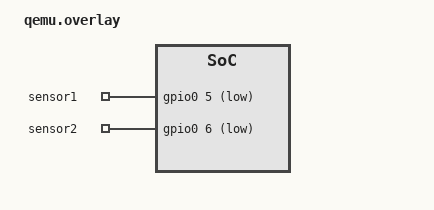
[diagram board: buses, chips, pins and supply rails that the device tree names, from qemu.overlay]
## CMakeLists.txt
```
# SPDX-License-Identifier: Apache-2.0

cmake_minimum_required(VERSION 3.20.0)

find_package(Zephyr REQUIRED HINTS $ENV{ZEPHYR_BASE})
project(my_app)

set(ZEPHYR_EXTRA_KCONFIG_FILES ${CMAKE_CURRENT_SOURCE_DIR}/Kconfig)
set(ZEPHYR_EXTRA_MODULES "${CMAKE_CURRENT_SOURCE_DIR}/camera_service/")


zephyr_include_directories(
    ${CMAKE_CURRENT_SOURCE_DIR}/include
    ${CMAKE_CURRENT_SOURCE_DIR}/camera_service/include
)
target_sources(app PRIVATE 
    src/main.c 
    src/sensor.c 
    src/ntp.c
    src/http_client.c
    src/http_sender.c
    src/camera_capture.c
    camera_service/src/camera_service.c)
```

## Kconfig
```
mainmenu "Radar Simplificado Configuration"

source "Kconfig.zephyr"

menu "My Project Options"

config RADAR_SENSOR_DISTANCE_MM
    int "Distância entre os sensores dada em milímetros."
    default 2000

config RADAR_SPEED_LIMIT_KMH
    int "Limite da via em Km por hora."
    default 60

config RADAR_CAMERA_FAILURE_RATE_PERCENT
    int "Porcentagem de chance da câmera simular uma falha e retornar uma placa inválida."
    default 0
    range 0 100


config SERVER_HOST
    string "Cloud server host"
    default "10.0.2.2"
    
config SERVER_PORT
    int "Cloud server port"
    default 8000
config SERVER_URL
    string "Cloud server url to send infractions"
    default "/notify-infraction"



endmenu
```

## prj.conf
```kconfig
# GENERAL CONFIGURATION
CONFIG_PRINTK=y
CONFIG_CONSOLE=y
CONFIG_UART_CONSOLE=y
CONFIG_NEWLIB_LIBC=y

# RADAR CONFIGURATION
CONFIG_RADAR_SENSOR_DISTANCE_MM=2000
CONFIG_RADAR_SPEED_LIMIT_KMH=60
CONFIG_RADAR_CAMERA_FAILURE_RATE_PERCENT=0

# ZBUS CONFIGURATION
CONFIG_ZBUS=y
CONFIG_ZBUS_MSG_SUBSCRIBER=y
CONFIG_TEST_RANDOM_GENERATOR=y
CONFIG_QEMU_ICOUNT=n

# GPIO CONFIGURATION
CONFIG_GPIO=y
CONFIG_GPIO_STELLARIS=y
CONFIG_GPIO_GET_CONFIG=y

# NETWORKING CONFIGURATION
CONFIG_POSIX_API=y
CONFIG_NETWORKING=y

# IPv4/IPv6 and protocols
CONFIG_NET_IPV4=y
CONFIG_NET_IPV6=y
CONFIG_NET_UDP=y
CONFIG_NET_TCP=y
CONFIG_NET_L2_ETHERNET=y
CONFIG_ETH_STELLARIS=y

# Sockets and connection
CONFIG_NET_SOCKETS=y
CONFIG_NET_SOCKETS_POLL_MAX=5
CONFIG_NET_CONTEXT_NET_PKT_POOL=y
CONFIG_NET_CONNECTION_MANAGER=y

# DHCP support
CONFIG_NET_DHCPV4=y
CONFIG_NET_DHCPV6=y

# DNS
CONFIG_DNS_RESOLVER=y
CONFIG_DNS_SERVER_IP_ADDRESSES=y
CONFIG_DNS_SERVER1="8.8.8.8"

# SNTP/NTP
CONFIG_SNTP=y

# Network buffers
CONFIG_NET_BUF_RX_COUNT=16
CONFIG_NET_BUF_TX_COUNT=16
CONFIG_NET_PKT_RX_COUNT=16
CONFIG_NET_PKT_TX_COUNT=16

# Network configuration and auto-init
CONFIG_NET_CONFIG_SETTINGS=y
CONFIG_NET_CONFIG_AUTO_INIT=y
CONFIG_NET_CONFIG_NEED_IPV4=y

# QEMU Network interface
CONFIG_NET_QEMU_ETHERNET=y
CONFIG_NET_QEMU_USER=y
CONFIG_NET_SLIP_TAP=n

# Network Management
CONFIG_NET_MGMT=y
CONFIG_NET_MGMT_EVENT=y
CONFIG_NET_MGMT_EVENT_INFO=y

CONFIG_SERVER_HOST="10.0.2.2"
CONFIG_SERVER_PORT=8000
CONFIG_SERVER_URL="/notify-infraction"
```

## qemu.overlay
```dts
#include <zephyr/dt-bindings/gpio/gpio.h>
/ {
    aliases {
        sensor1 = &gpio0;
        sensor2 = &gpio0;
    };

    sensors {
        compatible = "gpio-keys";
        debounce-interval-ms = <10>;
        sensor1: sensor_1{
            gpios = <&gpio0 5 GPIO_ACTIVE_LOW>;
        };

        sensor2: sensor_2{
            gpios = <&gpio0 6 GPIO_ACTIVE_LOW>;
        };
    };
    
};
```

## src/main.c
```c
#include <zephyr/kernel.h>
#include "sensor.h"
#include "camera_capture.h"

int main(void) {

    return 0; 
}

K_THREAD_DEFINE(sensor_thread_id, 1024, sensor_thread, NULL, NULL, NULL, 4, 0, 0);
K_THREAD_DEFINE(camera_capture_thread_id, 1024, camera_capture_thread, NULL, NULL, NULL, 4, 0, 0);
```

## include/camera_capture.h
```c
void camera_capture_thread(void *, void *, void *);
```

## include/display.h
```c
#ifndef DISPLAY_H
#define DISPLAY_H

void display_thread(void *, void *, void *);

#endif
```

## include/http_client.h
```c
/**
 * @brief Sends a traffic infraction notification to the cloud server.
 *
 * @param plate         The license plate of the vehicle.
 * @param speed_kmh     The recorded speed of the vehicle (in km/h).
 * @param timestamp     The timestamp of the infraction in ISO 8601 format.
 * @param image_hash    The hash string representing the image captured.
 *
 * @return 0 on success, negative error code on failure.
 */
int send_infraction_notification(const char *plate, int speed_kmh, const char *timestamp, const char *image_hash);
```

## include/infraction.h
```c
#define MAX_PLATE_LEN 16
#define MAX_HASH_LEN 62
#define MAX_TIMESTAMP_LEN 32

struct infraction_data {
    int speed_record;
    char plate[MAX_PLATE_LEN];
    char timestamp[MAX_TIMESTAMP_LEN];
    char image_hash[MAX_HASH_LEN];
};

extern struct k_msgq infraction_msgq;
```

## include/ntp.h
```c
#include <time.h>

int get_current_time(struct tm *out_time, int8_t timezone_offset_hours);
```

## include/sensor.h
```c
#ifndef SENSOR_H
#define SENSOR_H

#include <zephyr/kernel.h>
#include <zephyr/zbus/zbus.h>
#include <zephyr/drivers/gpio.h>

enum sensor_event_type {
    SENSOR_EVENT_VEHICLE_DETECTED,
    SENSOR_EVENT_SPEED_CALCULATED
};

struct sensor_event {
    enum sensor_event_type type;
    int speed_kmh;
    bool vehicle_detected;
    bool speed_exceeded;
};

void sensor_thread(void *, void *, void *);

ZBUS_CHAN_DECLARE(sensor_chan);

#endif /* SENSOR_H */
```

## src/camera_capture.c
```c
#include "ntp.h"
#include <time.h>
#include <zephyr/random/random.h>
#include "camera_service.h"
#include "infraction.h"
#include "sensor.h"
#include <stdio.h>
#include <zephyr/zbus/zbus.h>

ZBUS_MSG_SUBSCRIBER_DEFINE(msub_camera_evt);
ZBUS_MSG_SUBSCRIBER_DEFINE(msub_sensor_evt); 

ZBUS_CHAN_DEFINE(sensor_chan,             
         struct sensor_event,    
         NULL,                          
         NULL,                           
         ZBUS_OBSERVERS(msub_sensor_evt),           
         ZBUS_MSG_INIT(0)                
);

K_MSGQ_DEFINE(infraction_msgq, sizeof(struct infraction_data), 4, 4);


int should_call_camera() {
    if (CONFIG_RADAR_CAMERA_FAILURE_RATE_PERCENT > 0) {
        if ((sys_rand32_get() % 100) < CONFIG_RADAR_CAMERA_FAILURE_RATE_PERCENT) {
            printk("Camera failed to trigger (simulated)\n");
            return 0;
        }
    }
    return 1; 
}

int send_infraction(const char *plate, int speed_kmh, const char *timestamp, const char *image_hash) {

    struct infraction_data data = {
        .speed_record = speed_kmh
    };
    strncpy(data.plate, plate, MAX_PLATE_LEN);
    strncpy(data.timestamp, timestamp, MAX_TIMESTAMP_LEN);
    strncpy(data.image_hash, image_hash, MAX_HASH_LEN);

    return k_msgq_put(&infraction_msgq, &data, K_NO_WAIT);
}


int is_valid_plate(const char *plate) {
    int letter_counter = 0; 
    int number_counter = 0; 
    for (int i = 0; plate[i] != '\0'; i++) {

        if (plate[i] == ' ') {
            continue; 
        } 

        if (plate[i] >= 48 && plate[i] <= 57) {
            number_counter++;
            continue;
        } 
        
        if (plate[i] >= 65 && plate[i] <= 90) {
            letter_counter++;
            continue;
        }
    }

    if (letter_counter == 4 && number_counter == 3) {
        return 1; 
    } 

    return 0; 

}

void camera_capture_thread(void *, void *, void *) {
    const struct zbus_channel *chan;
    struct msg_camera_evt cam_evt;
    struct sensor_event sensor_evt;
    struct tm current_time;
    int err;

    while (1) {
        err = zbus_sub_wait_msg(&msub_sensor_evt, &chan, &sensor_evt, K_MSEC(100));

        if (!err && chan == &sensor_chan) {
            switch (sensor_evt.type) {
                case SENSOR_EVENT_VEHICLE_DETECTED:
                    printk("Vehicle detected at first sensor\n");
                    break;
                    
                case SENSOR_EVENT_SPEED_CALCULATED:
                    printk("Speed calculated: %d km/h (%s limit)\n", 
                           sensor_evt.speed_kmh,
                           sensor_evt.speed_exceeded ? "ABOVE" : "below");
                    
                    if (sensor_evt.speed_exceeded && should_call_camera()) {
                        printk("Triggering camera for speeding vehicle\n");
                        camera_api_capture(K_MSEC(100));
                    }
                    break;
            }
            continue;  
        }

        err = zbus_sub_wait_msg(&msub_camera_evt, &chan, &cam_evt, K_MSEC(100));
        if (!err) {
            switch (cam_evt.type) {
                case MSG_CAMERA_EVT_TYPE_DATA:
                    if (is_valid_plate(cam_evt.captured_data->plate)) {
                        
                        
                        const char *plate = cam_evt.captured_data->plate;
                        const char *hash = cam_evt.captured_data->hash;
                        
                        
                        get_current_time(&current_time, 0);
                        char formatted_timestamp[32]; 
                        snprintf(formatted_timestamp, sizeof(formatted_timestamp),
                        "%04d-%02d-%02d %02d:%02d:%02d",
                        current_time.tm_year + 1900, current_time.tm_mon + 1, 
                        current_time.tm_mday, current_time.tm_hour, 
                        current_time.tm_min, current_time.tm_sec);

                        printk("Valid plate captured: %s at %02d:%02d:%02d\n",
                               cam_evt.captured_data->plate,
                               current_time.tm_hour,
                               current_time.tm_min,
                               current_time.tm_sec);
                        
                               
                        int err = send_infraction(plate, sensor_evt.speed_kmh,formatted_timestamp, hash);
                        if (err != 0) {
                            printk("There was an error sending the infraction.\n");
                        }


                    } else {
                        printk("Invalid plate captured: %s at %02d:%02d:%02d\n", 
                            cam_evt.captured_data->plate,
                            current_time.tm_hour,
                            current_time.tm_min,
                            current_time.tm_sec);
                    }
                    break;
                    
                case MSG_CAMERA_EVT_TYPE_ERROR:
                    printk("Camera error: %d\n", cam_evt.error_code);
                    break;
                    
                default:
                    printk("Unknown camera event type: %d\n", cam_evt.type);
                    break;
            }
        }

    }
}
```

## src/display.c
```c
#include <zephyr/kernel.h>
#include <zephyr/sys/printk.h>
#include "display.h"

void display_thread(void *a, void *b, void *c) {
    while (1) {
        printk("Display thread rodando...\n");
        k_msleep(1000);
    }
}
```

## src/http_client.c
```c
#include <zephyr/net/socket.h>
#include <zephyr/net/http/client.h>
#include <zephyr/net/net_ip.h>
#include <stdio.h>
#include <string.h>
#include "http_client.h"

#define SERVER_HOST CONFIG_SERVER_HOST  
#define SERVER_PORT CONFIG_SERVER_PORT
#define SERVER_URL CONFIG_SERVER_URL

int send_infraction_notification(const char *plate, int speed, const char *timestamp, const char *image_hash) {
    int sock;
    struct sockaddr_in server_addr;
    char request_buf[1024];
    char response_buf[512];
    char json_payload[512];

    snprintf(json_payload, sizeof(json_payload),
        "{ \"plate\": \"%s\", \"timestamp\": \"%s\", \"recorded_speed\": %d, \"image_hash\": \"%s\" }",
        plate, timestamp, speed, image_hash);

    snprintf(request_buf, sizeof(request_buf),
        "POST %s HTTP/1.1\r\n"
        "Host: %s:%d\r\n"
        "Content-Type: application/json\r\n"
        "Content-Length: %zu\r\n"
        "\r\n"
        "%s",
        SERVER_URL, SERVER_HOST, SERVER_PORT,
        strlen(json_payload), json_payload);

    sock = socket(AF_INET, SOCK_STREAM, IPPROTO_TCP);
    if (sock < 0) {
        printk("Failed to create socket\n");
        return -1;
    }

    server_addr.sin_family = AF_INET;
    server_addr.sin_port = htons(SERVER_PORT);
    inet_pton(AF_INET, SERVER_HOST, &server_addr.sin_addr);

    if (connect(sock, (struct sockaddr *)&server_addr, sizeof(server_addr)) < 0) {
        printk("Failed to connect to server\n");
        close(sock);
        return -1;
    }

    send(sock, request_buf, strlen(request_buf), 0);
    int received = recv(sock, response_buf, sizeof(response_buf) - 1, 0);
    if (received > 0) {
        response_buf[received] = '\0';
        printk("--------------------\n");
        printk("Server response from notification:\n%s\n", response_buf);
        printk("--------------------\n");
    } else {
        printk("No response received from server\n");
    }

    close(sock);

    return 0;
}
```

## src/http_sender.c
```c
#include "camera_capture.h"
#include "infraction.h" 
#include "http_client.h"
#include <zephyr/kernel.h>

void http_sender_thread(void)
{
    struct infraction_data data;

    while (1) {
        printk("Waiting for infraction data...\n");
        k_msgq_get(&infraction_msgq, &data, K_FOREVER);
        printk("Got infraction data, sending notification...\n");
        int err = send_infraction_notification(data.plate, data.speed_record, data.timestamp, data.image_hash);
    }
}

K_THREAD_DEFINE(http_sender_thread_id, 4096, http_sender_thread, NULL, NULL, NULL, 5, 0, 0);
```

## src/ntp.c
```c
#include <zephyr/net/sntp.h>
#include <zephyr/net/socket.h>
#include <zephyr/logging/log.h>
#include <time.h>
#include <string.h>


#define SNTP_SERVER "129.6.15.28"

int get_current_time(struct tm *out_time, int8_t timezone_offset_hours)
{
    struct sntp_ctx ctx;
    struct sntp_time sntp_time;
    struct sockaddr_in addr;
    int err;

    memset(&ctx, 0, sizeof(ctx));
    memset(&addr, 0, sizeof(addr));

    addr.sin_family = AF_INET;
    addr.sin_port = htons(123);  // SNTP port

    err = inet_pton(AF_INET, SNTP_SERVER, &addr.sin_addr);
    if (err <= 0) {
        printk("Invalid SNTP server address");
        return -EINVAL;
    }

    
    err = sntp_init(&ctx, (struct sockaddr *)&addr, sizeof(addr));
    if (err < 0) {
        printk("SNTP init failed: %d", err);
        return err;
    }
    
    err = sntp_query(&ctx, 4000, &sntp_time);  
    sntp_close(&ctx);
    
    if (err < 0) {
        printk("SNTP query failed: %d", err);
        return err;
    }
    
    time_t unix_time = sntp_time.seconds + (timezone_offset_hours * 3600);
    if (gmtime_r(&unix_time, out_time) == NULL) {
        printk("Failed to convert to UTC time");
        return -EIO;
    }
    
    

    return 0;
}
```

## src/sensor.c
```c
#include "sensor.h"
#include <zephyr/kernel.h>
#include <zephyr/drivers/gpio.h>
#include <zephyr/logging/log.h>
#include <math.h>
#include <zephyr/random/random.h> 


#define MIN_DELAY_MS 50
#define MAX_DELAY_MS 200


#define SENSOR_DISTANCE_MM CONFIG_RADAR_SENSOR_DISTANCE_MM
#define SPEED_LIMIT_KMH CONFIG_RADAR_SPEED_LIMIT_KMH

#define SENSOR1_NODE DT_NODELABEL(sensor1)
#define SENSOR2_NODE DT_NODELABEL(sensor2)

static const struct gpio_dt_spec sensor1 = GPIO_DT_SPEC_GET(SENSOR1_NODE, gpios);
static const struct gpio_dt_spec sensor2 = GPIO_DT_SPEC_GET(SENSOR2_NODE, gpios);

static int64_t first_sensor_time = 0;
static bool vehicle_passed_first = false;

static void sensor1_callback(const struct device *dev, struct gpio_callback *cb,
                           uint32_t pins)
{
    if (!vehicle_passed_first) {
        first_sensor_time = k_uptime_get();
        vehicle_passed_first = true;
        
        struct sensor_event evt = {
            .type = SENSOR_EVENT_VEHICLE_DETECTED,
            .vehicle_detected = true,
            .speed_exceeded = false,
            .speed_kmh = 0
        };
        
        zbus_chan_pub(&sensor_chan, &evt, K_MSEC(100));
    }
}

static void sensor2_callback(const struct device *dev, struct gpio_callback *cb,
                           uint32_t pins)
{
    if (vehicle_passed_first) {
        int64_t second_sensor_time = k_uptime_get();
        int64_t time_diff_ms = second_sensor_time - first_sensor_time;
        
        double distance_km = SENSOR_DISTANCE_MM / 1000000.0;
        double time_h = time_diff_ms / (3600.0 * 1000.0);
        int speed_kmh = (int)(distance_km / time_h);
        
        struct sensor_event evt = {
            .type = SENSOR_EVENT_SPEED_CALCULATED,
            .speed_kmh = speed_kmh,
            .vehicle_detected = true,
            .speed_exceeded = (speed_kmh > SPEED_LIMIT_KMH)
        };
        
        zbus_chan_pub(&sensor_chan, &evt, K_MSEC(100));
        printk("Vehicle speed: %d km/h (%s limit)\n", 
               speed_kmh, evt.speed_exceeded ? "above" : "below");
        
        vehicle_passed_first = false;
    }
}

static struct gpio_callback sensor1_cb_data;
static struct gpio_callback sensor2_cb_data;

void sensor_thread(void *, void *, void *)
{
    if (!device_is_ready(sensor1.port) || !device_is_ready(sensor2.port)) {
        printk("Sensor GPIO devices not ready\n");
        return;
    }
    
    int ret = gpio_pin_configure_dt(&sensor1, GPIO_INPUT);
    ret |= gpio_pin_configure_dt(&sensor2, GPIO_INPUT);
    if (ret != 0) {
        printk("Failed to configure sensor GPIO pins\n");
        return;
    }
    
    ret = gpio_pin_interrupt_configure_dt(&sensor1, GPIO_INT_EDGE_RISING);
    ret |= gpio_pin_interrupt_configure_dt(&sensor2, GPIO_INT_EDGE_RISING);
    if (ret != 0) {
        printk("Failed to configure sensor interrupts\n");
        return;
    }
    
    gpio_init_callback(&sensor1_cb_data, sensor1_callback, BIT(sensor1.pin));
    gpio_init_callback(&sensor2_cb_data, sensor2_callback, BIT(sensor2.pin));
    
    gpio_add_callback(sensor1.port, &sensor1_cb_data);
    gpio_add_callback(sensor2.port, &sensor2_cb_data);
    
    printk("Sensor GPIO initialized\n");
    
    while (1) {
        k_msleep(5000);
        // Simulate sensor 1 trigger
        sensor1_callback(NULL, NULL, 0);

        uint32_t delay_ms = MIN_DELAY_MS + (sys_rand32_get() % (MAX_DELAY_MS - MIN_DELAY_MS + 1));
        printk("Simulated delay: %u ms\n", delay_ms);
        k_msleep(delay_ms); 
        // Simulate sensor 2 trigger
        sensor2_callback(NULL, NULL, 0);
    }
}
```
